VERSION ""

NS_ :

BS_:

BU_: VCU INV BMS DASH

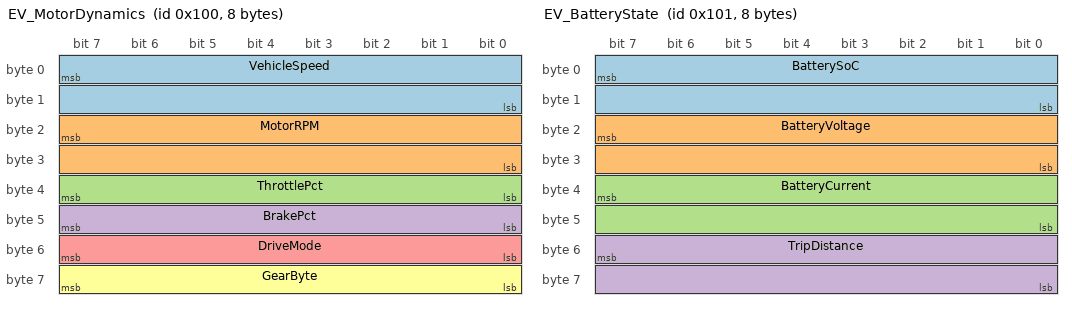
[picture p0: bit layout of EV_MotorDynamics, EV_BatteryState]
BO_ 256 EV_MotorDynamics: 8 VCU
 SG_ VehicleSpeed : 7|16@0+ (0.1,0) [0|300] "km/h" DASH
 SG_ MotorRPM : 23|16@0+ (1,0) [0|12000] "rpm" DASH
 SG_ ThrottlePct : 39|8@0+ (1,0) [0|100] "%" DASH
 SG_ BrakePct : 47|8@0+ (1,0) [0|100] "%" DASH
 SG_ DriveMode : 55|8@0+ (1,0) [0|3] "" DASH
 SG_ GearByte : 63|8@0+ (1,0) [0|255] "" DASH

BO_ 257 EV_BatteryState: 8 BMS
 SG_ BatterySoC : 7|16@0+ (0.1,0) [0|100] "%" DASH
 SG_ BatteryVoltage : 23|16@0+ (0.1,0) [0|500] "V" DASH
 SG_ BatteryCurrent : 39|16@0- (0.1,0) [-500|500] "A" DASH
 SG_ TripDistance : 55|16@0+ (0.1,0) [0|6553.5] "km" DASH

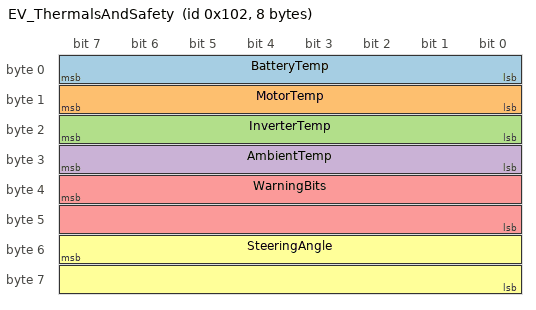
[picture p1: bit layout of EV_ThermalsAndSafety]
BO_ 258 EV_ThermalsAndSafety: 8 VCU
 SG_ BatteryTemp : 7|8@0+ (1,-40) [-40|120] "degC" DASH
 SG_ MotorTemp : 15|8@0+ (1,-40) [-40|200] "degC" DASH
 SG_ InverterTemp : 23|8@0+ (1,-40) [-40|150] "degC" DASH
 SG_ AmbientTemp : 31|8@0+ (1,-40) [-40|80] "degC" DASH
 SG_ WarningBits : 39|16@0+ (1,0) [0|65535] "" DASH
 SG_ SteeringAngle : 55|16@0- (0.1,0) [-720|720] "deg" DASH

CM_ BO_ 256 "High-frequency dynamic powertrain signals";
CM_ BO_ 257 "High-voltage battery pack status";
CM_ BO_ 258 "Powertrain thermal monitoring and safety warnings";

VAL_ 256 DriveMode 0 "ECO" 1 "DRIVE" 2 "SPORT" ;
